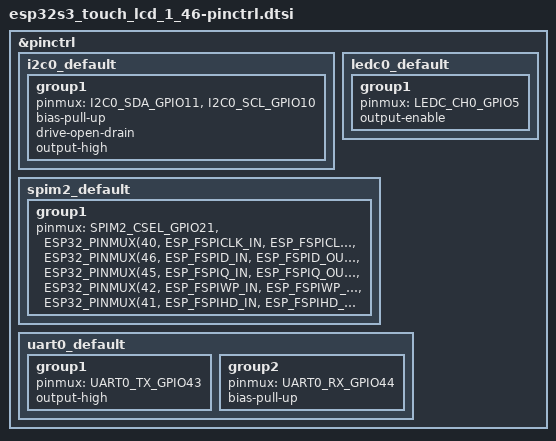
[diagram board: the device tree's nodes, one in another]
/*
 * Copyright (c) 2025 Gratian Crisan
 * SPDX-License-Identifier: Apache-2.0
 */

#include <zephyr/dt-bindings/pinctrl/esp-pinctrl-common.h>
#include <dt-bindings/pinctrl/esp32s3-pinctrl.h>
#include <zephyr/dt-bindings/pinctrl/esp32s3-gpio-sigmap.h>
#include <zephyr/dt-bindings/pwm/pwm.h>

&pinctrl {

	i2c0_default: i2c0_default {
		group1 {
			pinmux = <I2C0_SDA_GPIO11>, <I2C0_SCL_GPIO10>;
			bias-pull-up;
			drive-open-drain;
			output-high;
		};
	};

	ledc0_default: ledc0_default {
		group1 {
			pinmux = <LEDC_CH0_GPIO5>;
			output-enable;
		};
	};

	/*
	GPIO numbers for LCD connection:
	  LCD_SPI_IO_TE             (18)
	  LCD_SPI_IO_SCK            (40) // SCLK
	  LCD_SPI_IO_DATA0          (46) // MOSI
	  LCD_SPI_IO_DATA1          (45) // MISO
	  LCD_SPI_IO_DATA2          (42) // QUADWP
	  LCD_SPI_IO_DATA3          (41) // QUADHD
	  LCD_SPI_IO_CS             (21)
	*/
	spim2_default: spim2_default {
		group1 {
			pinmux = <SPIM2_CSEL_GPIO21>,
				<ESP32_PINMUX(40, ESP_FSPICLK_IN, ESP_FSPICLK_OUT)>,
				<ESP32_PINMUX(46, ESP_FSPID_IN, ESP_FSPID_OUT)>,
				<ESP32_PINMUX(45, ESP_FSPIQ_IN, ESP_FSPIQ_OUT)>,
				<ESP32_PINMUX(42, ESP_FSPIWP_IN, ESP_FSPIWP_OUT)>,
				<ESP32_PINMUX(41, ESP_FSPIHD_IN, ESP_FSPIHD_OUT)>;
		};
	};

	uart0_default: uart0_default {
		group1 {
			pinmux = <UART0_TX_GPIO43>;
			output-high;
		};
		group2 {
			pinmux = <UART0_RX_GPIO44>;
			bias-pull-up;
		};
	};
};

